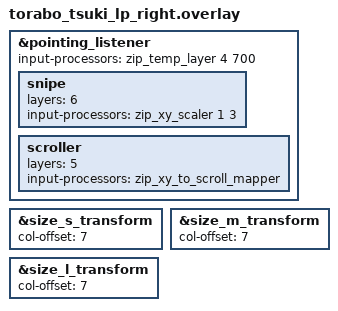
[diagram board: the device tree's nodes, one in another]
#include "torabo_tsuki_lp.dtsi"
#include <input/processors.dtsi>
#include <dt-bindings/zmk/input_transform.h>

&pointing_listener {
    input-processors = <&zip_xy_transform (INPUT_TRANSFORM_X_INVERT | INPUT_TRANSFORM_Y_INVERT)>;
    //ADD Snipe, SCROLL and AML 
    snipe {
        layers = <6>;
        input-processors = <&zip_xy_scaler 1 3>;
    };
    scroller {
        layers = <5>;
        input-processors = <&zip_xy_to_scroll_mapper>;
    };
    input-processors = <&zip_temp_layer 4 700>;
};

&size_s_transform {
    col-offset = <7>;
};

&size_m_transform {
    col-offset = <7>;
};

&size_l_transform {
    col-offset = <7>;
};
